# f1c100s register map
Vendor: Allwinner; File version: 1.0
Registers are 32-bit, read-write, reset 0x0 unless marked. A register's access mark holds for its fields unless they carry their own. Offsets are from the block's base; [hi:lo] are bit positions; {n}, {i} and the like mark numbered series.

## TIMER — Timer, Watchdog and AVS Counter
Base 0x01C20C00
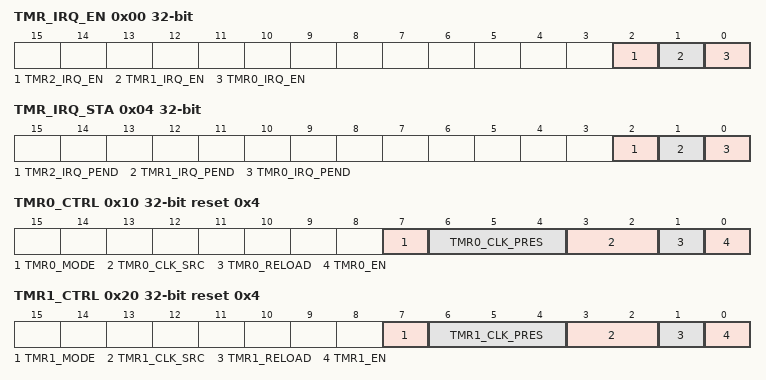
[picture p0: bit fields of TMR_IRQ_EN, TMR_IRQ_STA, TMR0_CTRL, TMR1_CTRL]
0x00 TMR_IRQ_EN — Timer IRQ Enable Register
  [2] TMR2_IRQ_EN — Timer 2 Interrupt Enable
  [1] TMR1_IRQ_EN — Timer 1 Interrupt Enable
  [0] TMR0_IRQ_EN — Timer 0 Interrupt Enable
0x04 TMR_IRQ_STA — Timer Status Register
  [2] TMR2_IRQ_PEND — Timer 2 IRQ Pending (write 1 to clear)
  [1] TMR1_IRQ_PEND — Timer 1 IRQ Pending (write 1 to clear)
  [0] TMR0_IRQ_PEND — Timer 0 IRQ Pending (write 1 to clear)
0x10 TMR0_CTRL reset 0x4 — Timer 0 Control Register
  [7] TMR0_MODE — Timer 0 Mode (0: Continuous, 1: Single)
  [6:4] TMR0_CLK_PRES — Timer 0 Clock Prescale
  [3:2] TMR0_CLK_SRC — Timer 0 Clock Source (0: LOSC, 1: OSC24M)
  [1] TMR0_RELOAD — Timer 0 Reload
  [0] TMR0_EN — Timer 0 Enable
{0x14+0x10*i} TMR{i}_INTV (i=0..2) — Timer {i} Interval Value Register
  [31:0] TMR{i}_INTV — Timer {i} Interval Value
{0x18+0x10*i} TMR{i}_CUR ro (i=0..2) — Timer {i} Current Value Register
  [31:0] TMR{i}_CUR — Timer {i} Current Value
0x20 TMR1_CTRL reset 0x4 — Timer 1 Control Register
  [7] TMR1_MODE — Timer 1 Mode
  [6:4] TMR1_CLK_PRES — Timer 1 Clock Prescale
  [3:2] TMR1_CLK_SRC — Timer 1 Clock Source
  [1] TMR1_RELOAD — Timer 1 Reload
  [0] TMR1_EN — Timer 1 Enable
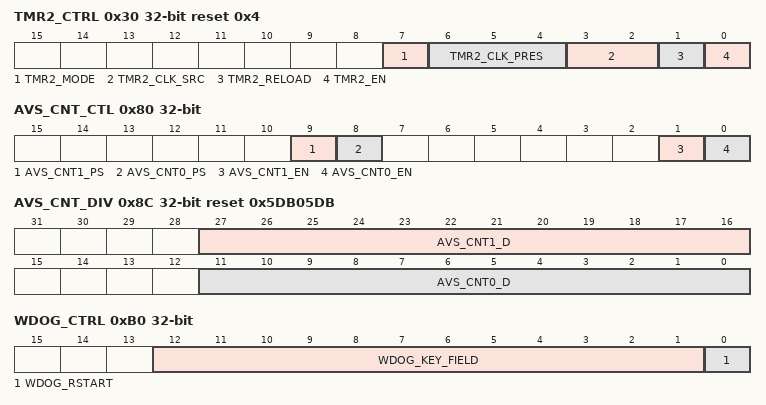
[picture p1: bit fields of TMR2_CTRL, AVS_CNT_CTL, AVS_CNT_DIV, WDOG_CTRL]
0x30 TMR2_CTRL reset 0x4 — Timer 2 Control Register
  [7] TMR2_MODE — Timer 2 Mode
  [6:4] TMR2_CLK_PRES — Timer 2 Clock Prescale
  [3:2] TMR2_CLK_SRC — Timer 2 Clock Source
  [1] TMR2_RELOAD — Timer 2 Reload
  [0] TMR2_EN — Timer 2 Enable
0x80 AVS_CNT_CTL — AVS Counter Control Register
  [9] AVS_CNT1_PS — AVS Counter 1 Pause
  [8] AVS_CNT0_PS — AVS Counter 0 Pause
  [1] AVS_CNT1_EN — AVS Counter 1 Enable
  [0] AVS_CNT0_EN — AVS Counter 0 Enable
0x84 AVS_CNT0 — AVS Counter 0 Register
  [31:0] AVS_CNT0 — AVS Counter 0 Value
0x88 AVS_CNT1 — AVS Counter 1 Register
  [31:0] AVS_CNT1 — AVS Counter 1 Value
0x8C AVS_CNT_DIV reset 0x5DB05DB — AVS Counter Divisor Register
  [27:16] AVS_CNT1_D — Divisor N for AVS Counter 1
  [11:0] AVS_CNT0_D — Divisor N for AVS Counter 0
0xA0 WDOG_IRQ_EN — Watchdog IRQ Enable Register
  [0] WDOG_IRQ_EN — Watchdog Interrupt Enable
0xA4 WDOG_IRQ_STA — Watchdog Status Register
  [0] WDOG_IRQ_PEND — Watchdog IRQ Pending (write 1 to clear)
0xB0 WDOG_CTRL — Watchdog Control Register
  [12:1] WDOG_KEY_FIELD — Watchdog Key Field (must write 0xA57)
  [0] WDOG_RSTART — Watchdog Restart
0xB4 WDOG_CFG reset 0x1 — Watchdog Configuration Register
  [1:0] WDOG_CONFIG — Watchdog Config (1: Reset whole system, 2: Only interrupt)
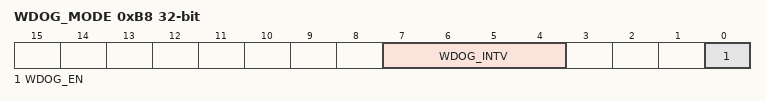
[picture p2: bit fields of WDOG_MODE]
0xB8 WDOG_MODE — Watchdog Mode Register
  [7:4] WDOG_INTV — Watchdog Interval Value
  [0] WDOG_EN — Watchdog Enable

## INTC — Interrupt Controller - Handles up to 64 interrupt sources with 4-level priority, fast forcing, and NMI support
Base 0x01C20400
0x00 INTC_VECTOR ro — Interrupt Vector Register
  [31:2] INTC_VECTOR_ADDR — Vector address for the interrupt currently active on the CPU IRQ input
0x04 INTC_BASE_ADDR — Interrupt Base Address Register
  [31:2] INTC_BASE_ADDR — Upper 30 bits of the base address of the vector table
0x0C NMI_INT_CTRL — NMI Interrupt Control Register
  [1:0] NMI_SRC_TYPE — External NMI Interrupt Source Type: 00=Low level, 01=Negative edge, 10=High level, 11=Positive edge
0x10 INTC_PEND_REG0 — Interrupt IRQ Pending Register 0
  [31:0] INTC_PEND0 — Interrupt Source [31:0] Pending/Clear Bit. 0=Not pending, 1=Pending
0x14 INTC_PEND_REG1 — Interrupt IRQ Pending Register 1
  [31:0] INTC_PEND1 — Interrupt Source [63:32] Pending/Clear Bit. 0=Not pending, 1=Pending
0x20 INTC_EN_REG0 — Interrupt Enable Register 0
  [31:0] INTC_EN0 — Interrupt Source [31:0] Enable Bits. 0=Disabled, 1=Enabled
0x24 INTC_EN_REG1 — Interrupt Enable Register 1
  [31:0] INTC_EN1 — Interrupt Source [63:32] Enable Bits. 0=Disabled, 1=Enabled
0x30 INTC_MASK_REG0 — Interrupt Mask Register 0
  [31:0] INTC_MASK0 — Interrupt Source [31:0] Mask Bits. 0=No effect, 1=Masked. Pending bit still set even if masked.
0x34 INTC_MASK_REG1 — Interrupt Mask Register 1
  [31:0] INTC_MASK1 — Interrupt Source [63:32] Mask Bits. 0=No effect, 1=Masked. Pending bit still set even if masked.
0x40 INTC_RESP_REG0 — Interrupt Response Register 0
  [31:0] INTC_RESP0 — Interrupt Response Bits [31:0]. If set, interrupts with lower or same priority are masked.
0x44 INTC_RESP_REG1 — Interrupt Response Register 1
  [31:0] INTC_RESP1 — Interrupt Response Bits [63:32]. If set, interrupts with lower or same priority are masked.
0x50 INTC_FF_REG0 — Interrupt Fast Forcing Register 0
  [31:0] INTC_FF0 — Fast forcing on interrupt source [31:0]. 0=No effect, 1=Force. Only valid when interrupt enable bit is set.
0x54 INTC_FF_REG1 — Interrupt Fast Forcing Register 1
  [31:0] INTC_FF1 — Fast forcing on interrupt source [63:32]. 0=No effect, 1=Force. Only valid when interrupt enable bit is set.
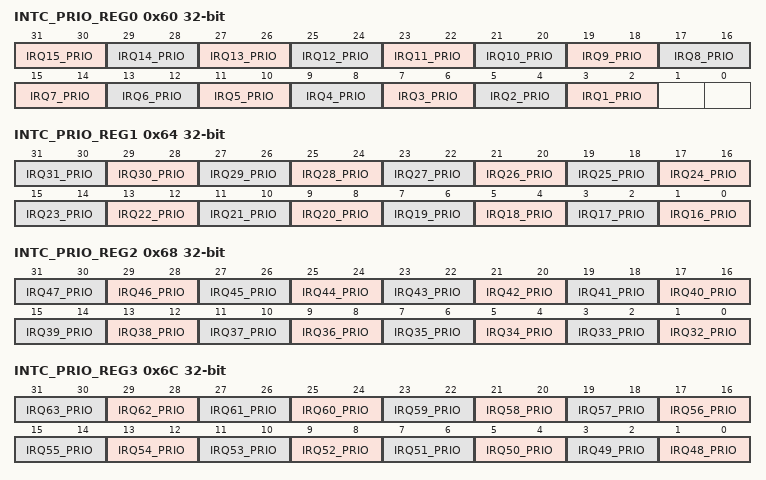
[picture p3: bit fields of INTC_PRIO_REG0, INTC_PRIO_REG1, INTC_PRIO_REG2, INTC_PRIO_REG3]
0x60 INTC_PRIO_REG0 — Interrupt Source Priority Register 0 (IRQ 1-15, 2-bit each, 4 levels)
  [2n+1:2n] IRQ{n}_PRIO (n=1..15) — IRQ {n} Priority. 0=Lowest, 3=Highest
0x64 INTC_PRIO_REG1 — Interrupt Source Priority Register 1 (IRQ 16-31, 2-bit each, 4 levels)
  [2n-31:2n-32] IRQ{n}_PRIO (n=16..31) — IRQ {n} Priority. 0=Lowest, 3=Highest
0x68 INTC_PRIO_REG2 — Interrupt Source Priority Register 2 (IRQ 32-47, 2-bit each, 4 levels)
  [2n-63:2n-64] IRQ{n}_PRIO (n=32..47) — IRQ {n} Priority. 0=Lowest, 3=Highest
0x6C INTC_PRIO_REG3 — Interrupt Source Priority Register 3 (IRQ 48-63, 2-bit each, 4 levels)
  [2n-95:2n-96] IRQ{n}_PRIO (n=48..63) — IRQ {n} Priority. 0=Lowest, 3=Highest
